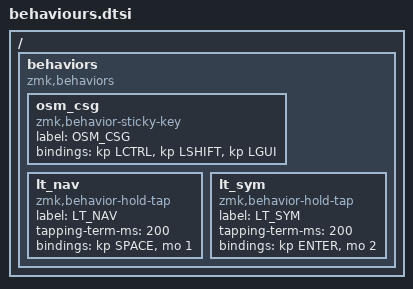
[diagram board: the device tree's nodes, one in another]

/ {
    behaviors {
        compatible = "zmk,behaviors";

        /* One-shot Ctrl+Shift+Gui */
        osm_csg: osm_csg {
            compatible = "zmk,behavior-sticky-key";
            label = "OSM_CSG";
            #binding-cells = <0>;
            bindings = <&kp LCTRL &kp LSHIFT &kp LGUI>;
        };

        /* Layer-tap thumbs */
        lt_nav: lt_nav {
            compatible = "zmk,behavior-hold-tap";
            label = "LT_NAV";
            #binding-cells = <2>;
            tapping-term-ms = <200>;
            bindings = <&kp SPACE &mo 1>;
        };

        lt_sym: lt_sym {
            compatible = "zmk,behavior-hold-tap";
            label = "LT_SYM";
            #binding-cells = <2>;
            tapping-term-ms = <200>;
            bindings = <&kp ENTER &mo 2>;
        };
    };
};

